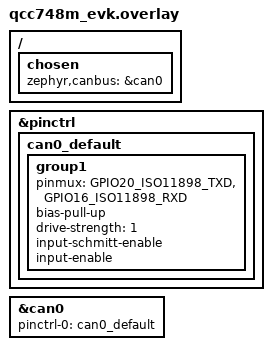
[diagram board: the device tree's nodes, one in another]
/*
 * Copyright (c) 2026 Qualcomm Technologies, Inc. and/or its subsidiaries
 *
 * SPDX-License-Identifier: Apache-2.0
 */

/ {
	chosen {
		zephyr,canbus = &can0;
	};
};

&pinctrl {
	can0_default: can0_default {
	group1 {
		pinmux = <GPIO20_ISO11898_TXD>,
			<GPIO16_ISO11898_RXD>;
		bias-pull-up;
		drive-strength = <1>;
		input-schmitt-enable;
		input-enable;
		};
	};
};

&can0 {
	status = "okay";
	pinctrl-0 = <&can0_default>;
	pinctrl-names = "default";
};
